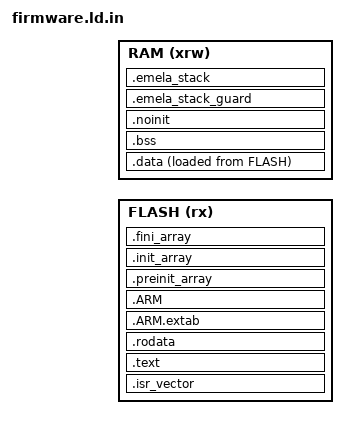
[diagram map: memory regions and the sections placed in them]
ENTRY(Reset_Handler)

/* Exceptions and thread mode share MSP; reserve its actual descending range. */
PROVIDE(__emela_stack_size = @STACK_BYTES@);
PROVIDE(__emela_stack_guard_size = @GUARD_BYTES@);
_Min_Heap_Size = 0;
_Min_Stack_Size = __emela_stack_size;

MEMORY
{
  FLASH (rx)  : ORIGIN = @FLASH_ORIGIN@, LENGTH = @FLASH_BYTES@
  RAM   (xrw) : ORIGIN = @RAM_ORIGIN@, LENGTH = @RAM_BYTES@
}

__emela_stack_top__ = ORIGIN(RAM) + LENGTH(RAM);
__emela_stack_bottom__ = __emela_stack_top__ - __emela_stack_size;
__emela_stack_guard_end__ = __emela_stack_bottom__;
__emela_stack_guard_start__ = __emela_stack_guard_end__ - __emela_stack_guard_size;
_estack = __emela_stack_top__;

ASSERT(__emela_stack_size > 0 && (__emela_stack_size % 8) == 0,
       "MSP stack size must be a positive multiple of 8")
ASSERT(__emela_stack_guard_size >= 32 && (__emela_stack_guard_size % 8) == 0,
       "MSP guard size must be at least 32 and a multiple of 8")
ASSERT(__emela_stack_guard_start__ >= ORIGIN(RAM), "MSP reservation exceeds RAM")

SECTIONS
{
  .isr_vector :
  {
    . = ALIGN(4);
    KEEP(*(.isr_vector))
    . = ALIGN(4);
  } > FLASH

  .text :
  {
    . = ALIGN(4);
    *(.text .text*)
    *(.glue_7 .glue_7t)
    *(.eh_frame)
    KEEP(*(.init))
    KEEP(*(.fini))
    . = ALIGN(4);
    _etext = .;
  } > FLASH

  .rodata :
  {
    . = ALIGN(4);
    *(.rodata .rodata*)
    . = ALIGN(4);
  } > FLASH

  .ARM.extab (READONLY) :
  {
    . = ALIGN(4);
    *(.ARM.extab* .gnu.linkonce.armextab.*)
    . = ALIGN(4);
  } > FLASH

  .ARM (READONLY) :
  {
    . = ALIGN(4);
    __exidx_start = .;
    *(.ARM.exidx*)
    __exidx_end = .;
    . = ALIGN(4);
  } > FLASH

  .preinit_array (READONLY) :
  {
    . = ALIGN(4);
    PROVIDE_HIDDEN(__preinit_array_start = .);
    KEEP(*(.preinit_array*))
    PROVIDE_HIDDEN(__preinit_array_end = .);
    . = ALIGN(4);
  } > FLASH

  .init_array (READONLY) :
  {
    . = ALIGN(4);
    PROVIDE_HIDDEN(__init_array_start = .);
    KEEP(*(SORT(.init_array.*)))
    KEEP(*(.init_array*))
    PROVIDE_HIDDEN(__init_array_end = .);
    . = ALIGN(4);
  } > FLASH

  .fini_array (READONLY) :
  {
    . = ALIGN(4);
    PROVIDE_HIDDEN(__fini_array_start = .);
    KEEP(*(SORT(.fini_array.*)))
    KEEP(*(.fini_array*))
    PROVIDE_HIDDEN(__fini_array_end = .);
    . = ALIGN(4);
  } > FLASH

  _sidata = LOADADDR(.data);
  .data :
  {
    . = ALIGN(4);
    _sdata = .;
    *(.data .data*)
    *(.RamFunc .RamFunc*)
    . = ALIGN(4);
    _edata = .;
  } > RAM AT> FLASH
  __emela_flash_image_end__ = LOADADDR(.data) + SIZEOF(.data);

  .bss :
  {
    . = ALIGN(4);
    _sbss = .;
    __bss_start__ = _sbss;
    *(.bss .bss*)
    *(COMMON)
    . = ALIGN(4);
    _ebss = .;
    __bss_end__ = .;
  } > RAM

  .noinit (NOLOAD) :
  {
    . = ALIGN(8);
    *(.noinit .noinit*)
    . = ALIGN(8);
  } > RAM
  __emela_static_ram_end__ = .;
  PROVIDE(end = .);
  PROVIDE(_end = .);
  PROVIDE(__HeapBase = .);
  PROVIDE(__HeapLimit = .);

  .emela_stack_guard __emela_stack_guard_start__ (NOLOAD) :
  {
    . += __emela_stack_guard_size;
  } > RAM

  .emela_stack __emela_stack_bottom__ (NOLOAD) :
  {
    . += __emela_stack_size;
  } > RAM

  ASSERT(__emela_static_ram_end__ <= __emela_stack_guard_start__,
         "static RAM overlaps MSP guard/stack")
  ASSERT(__emela_flash_image_end__ <= ORIGIN(FLASH) + LENGTH(FLASH),
         "Flash image including initialized data exceeds FLASH")

  .ARM.attributes 0 : { *(.ARM.attributes) }
}
